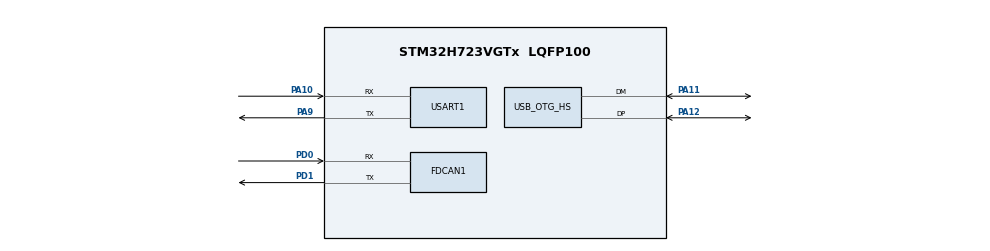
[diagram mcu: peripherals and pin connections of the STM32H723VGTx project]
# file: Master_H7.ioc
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FDCAN1.CalculateBaudRateNominal=1000000
FDCAN1.CalculateTimeBitNominal=1000
FDCAN1.CalculateTimeQuantumNominal=62.5
FDCAN1.DataPrescaler=6
FDCAN1.DataSyncJumpWidth=5
FDCAN1.DataTimeSeg1=8
FDCAN1.DataTimeSeg2=4
FDCAN1.ExtFiltersNbr=0
FDCAN1.MessageRAMOffset=0
FDCAN1.NominalPrescaler=6
FDCAN1.NominalSyncJumpWidth=5
FDCAN1.NominalTimeSeg1=9
FDCAN1.NominalTimeSeg2=6
FDCAN1.RxFifo0ElmtsNbr=64
FDCAN1.RxFifo1ElmtsNbr=64
FDCAN1.StdFiltersNbr=64
FDCAN1.TxFifoQueueElmtsNbr=32
Mcu.Family=STM32H7
Mcu.Name=STM32H723VGTx
Mcu.Package=LQFP100
NVIC.FDCAN1_IT0_IRQn=true\:0\:0\:false\:false\:true\:true\:true\:true
NVIC.OTG_HS_IRQn=true\:0\:0\:false\:false\:true\:false\:true\:true
NVIC.PriorityGroup=NVIC_PRIORITYGROUP_4
PA10.Mode=Asynchronous
PA10.Signal=USART1_RX
PA11.Mode=Device_Only_FS
PA11.Signal=USB_OTG_HS_DM
PA12.Mode=Device_Only_FS
PA12.Signal=USB_OTG_HS_DP
PA13(JTMS/SWDIO).Mode=Serial_Wire
PA13(JTMS/SWDIO).Signal=DEBUG_JTMS-SWDIO
PA14(JTCK/SWCLK).Mode=Serial_Wire
PA14(JTCK/SWCLK).Signal=DEBUG_JTCK-SWCLK
PA9.Mode=Asynchronous
PA9.Signal=USART1_TX
PD0.Mode=FDCAN_Activate
PD0.Signal=FDCAN1_RX
PD1.Mode=FDCAN_Activate
PD1.Signal=FDCAN1_TX
PH0-OSC_IN.Mode=HSE-External-Clock-Source
PH0-OSC_IN.Signal=RCC_OSC_IN
ProjectManager.HeapSize=0x200
ProjectManager.StackSize=0x400
ProjectManager.TargetToolchain=STM32CubeIDE
RCC.ADCFreq_Value=96000000
RCC.APB1Freq_Value=137500000
RCC.APB2Freq_Value=137500000
RCC.APB3Freq_Value=137500000
RCC.APB4Freq_Value=137500000
RCC.CortexFreq_Value=550000000
RCC.D1PPRE=RCC_APB3_DIV2
RCC.D2PPRE1=RCC_APB1_DIV2
RCC.D2PPRE2=RCC_APB2_DIV2
RCC.D3PPRE=RCC_APB4_DIV2
RCC.DIVM1=3
RCC.DIVM2=1
RCC.DIVN1=137
RCC.DIVN2=16
RCC.DIVP1=1
RCC.DIVQ1=5
RCC.FDCANCLockSelection=RCC_FDCANCLKSOURCE_PLL2
RCC.HCLKFreq_Value=275000000
RCC.HPRE=RCC_HCLK_DIV2
RCC.HSE_VALUE=12000000
RCC.PLL2FRACN=0
RCC.PLL3FRACN=0
RCC.PLLFRACN=4096
RCC.SYSCLKFreq_VALUE=550000000
RCC.SYSCLKSource=RCC_SYSCLKSOURCE_PLLCLK
RCC.USBFreq_Value=110000000
USART1.VirtualMode-Asynchronous=VM_ASYNC
USB_DEVICE.CLASS_NAME_HS=CDC
USB_DEVICE.VirtualMode=Cdc
USB_DEVICE.VirtualModeHS=Cdc_HS
USB_OTG_HS.VirtualMode-Device_Only_FS=Device_Only_FS
VP_USB_DEVICE_VS_USB_DEVICE_CDC_HS.Mode=CDC_HS
board=custom

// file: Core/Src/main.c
/* USER CODE BEGIN Header */
/**
  ******************************************************************************
  * @file           : main.c
  * @brief          : Main program body
  ******************************************************************************
  * @attention
  *
  * Copyright (c) 2024 STMicroelectronics.
  * All rights reserved.
  *
  * This software is licensed under terms that can be found in the LICENSE file
  * in the root directory of this software component.
  * If no LICENSE file comes with this software, it is provided AS-IS.
  *
  ******************************************************************************
  */
/* USER CODE END Header */
#include "main.h"
#include "fdcan.h"
#include "usart.h"
#include "usb_device.h"
#include "gpio.h"

/* USER CODE BEGIN Includes */
#include "bsp_retarget.h"
#include "bsp_can.h"
#include "slowStart.h"
/* USER CODE END Includes */

void SystemClock_Config(void);

int main(void) {

    /* MCU Configuration--------------------------------------------------------*/

    /* Reset of all peripherals, Initializes the Flash interface and the Systick. */
    HAL_Init();

    /* Configure the system clock */
    SystemClock_Config();

    /* Initialize all configured peripherals */
    MX_GPIO_Init();
    MX_FDCAN1_Init();
    MX_USART1_UART_Init();
    MX_USB_DEVICE_Init();
    /* USER CODE BEGIN 2 */
    fdcan_init();
    /* USER CODE END 2 */

    /* Infinite loop */
    /* USER CODE BEGIN WHILE */
    while (1) {
        sstart_allopen(&hfdcan1, 0x01);
        /* USER CODE END WHILE */

    }
}

void SystemClock_Config(void) {
    RCC_OscInitTypeDef RCC_OscInitStruct = {0};
    RCC_ClkInitTypeDef RCC_ClkInitStruct = {0};

    /** Supply configuration update enable
    */
    HAL_PWREx_ConfigSupply(PWR_LDO_SUPPLY);

    /** Configure the main internal regulator output voltage
    */
    __HAL_PWR_VOLTAGESCALING_CONFIG(PWR_REGULATOR_VOLTAGE_SCALE0);

    while (!__HAL_PWR_GET_FLAG(PWR_FLAG_VOSRDY)) {}

    /** Macro to configure the PLL clock source
    */
    __HAL_RCC_PLL_PLLSOURCE_CONFIG(RCC_PLLSOURCE_HSE);

    /** Initializes the RCC Oscillators according to the specified parameters
    * in the RCC_OscInitTypeDef structure.
    */
    RCC_OscInitStruct.OscillatorType = RCC_OSCILLATORTYPE_HSE;
    RCC_OscInitStruct.HSEState = RCC_HSE_BYPASS;
    RCC_OscInitStruct.PLL.PLLState = RCC_PLL_ON;
    RCC_OscInitStruct.PLL.PLLSource = RCC_PLLSOURCE_HSE;
    RCC_OscInitStruct.PLL.PLLM = 3;
    RCC_OscInitStruct.PLL.PLLN = 137;
    RCC_OscInitStruct.PLL.PLLP = 1;
    RCC_OscInitStruct.PLL.PLLQ = 5;
    RCC_OscInitStruct.PLL.PLLR = 2;
    RCC_OscInitStruct.PLL.PLLRGE = RCC_PLL1VCIRANGE_2;
    RCC_OscInitStruct.PLL.PLLVCOSEL = RCC_PLL1VCOWIDE;
    RCC_OscInitStruct.PLL.PLLFRACN = 4096;
    if (HAL_RCC_OscConfig(&RCC_OscInitStruct) != HAL_OK) {
        Error_Handler();
    }

    /** Initializes the CPU, AHB and APB buses clocks
    */
    RCC_ClkInitStruct.ClockType = RCC_CLOCKTYPE_HCLK | RCC_CLOCKTYPE_SYSCLK
                                  | RCC_CLOCKTYPE_PCLK1 | RCC_CLOCKTYPE_PCLK2
                                  | RCC_CLOCKTYPE_D3PCLK1 | RCC_CLOCKTYPE_D1PCLK1;
    RCC_ClkInitStruct.SYSCLKSource = RCC_SYSCLKSOURCE_PLLCLK;
    RCC_ClkInitStruct.SYSCLKDivider = RCC_SYSCLK_DIV1;
    RCC_ClkInitStruct.AHBCLKDivider = RCC_HCLK_DIV2;
    RCC_ClkInitStruct.APB3CLKDivider = RCC_APB3_DIV2;
    RCC_ClkInitStruct.APB1CLKDivider = RCC_APB1_DIV2;
    RCC_ClkInitStruct.APB2CLKDivider = RCC_APB2_DIV2;
    RCC_ClkInitStruct.APB4CLKDivider = RCC_APB4_DIV2;

    if (HAL_RCC_ClockConfig(&RCC_ClkInitStruct, FLASH_LATENCY_3) != HAL_OK) {
        Error_Handler();
    }
}

void Error_Handler(void) {
    __disable_irq();
    while (1) {
    }
}
